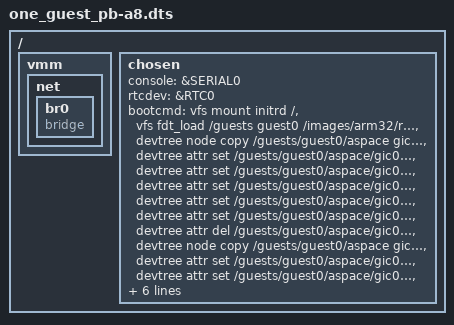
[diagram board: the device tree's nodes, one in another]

/dts-v1/;

#include "vexpress-a15.dtsi"

/ {
	vmm {
		net {
			br0 {
				device_type = "netswitch";
				compatible = "bridge";
			};
		};
	};

	chosen {
		console = &SERIAL0;
		rtcdev = &RTC0;
		bootcmd = /* Mount initrd device */
			  "vfs mount initrd /",

			  /* Load guest0 device tree from file */
			  "vfs fdt_load /guests guest0 /images/arm32/realview-pb-a8.dtb mem0,physical_size,physsize,0x06000000 net0,switch,string,br0 net1,switch,string,br0",

			  /* Replace guest0 GIC emulator with vGIC emulator */
			  "devtree node copy /guests/guest0/aspace gic0_cpu /guests/guest0/aspace/gic0",
			  "devtree attr set /guests/guest0/aspace/gic0_cpu manifest_type string real",
			  "devtree attr set /guests/guest0/aspace/gic0_cpu guest_physical_addr physaddr 0x1E000000",
			  "devtree attr set /guests/guest0/aspace/gic0_cpu host_physical_addr physaddr 0x0",
			  "devtree attr set /guests/guest0/aspace/gic0_cpu physical_size physsize 0x1000",
			  "devtree attr set /guests/guest0/aspace/gic0_cpu compatible string arm,vgic,cpu",
			  "devtree attr del /guests/guest0/aspace/gic0_cpu parent_irq",
			  "devtree node copy /guests/guest0/aspace gic0_dist /guests/guest0/aspace/gic0",
			  "devtree attr set /guests/guest0/aspace/gic0_dist guest_physical_addr physaddr 0x1E001000",
			  "devtree attr set /guests/guest0/aspace/gic0_dist physical_size physsize 0x1000",
			  "devtree attr set /guests/guest0/aspace/gic0_dist compatible string arm,vgic,dist",
			  "devtree attr set /guests/guest0/aspace/gic0_dist num_irq uint32 96",
			  "devtree node del /guests/guest0/aspace/gic0",

			  /* Create guest0 */
			  "guest create guest0",

			  /* Load guest0 images */
			  "vfs guest_load_list guest0 /images/arm32/realview-pb-a8/nor_flash.list",

			  /* Print banner */
			  "vfs cat /system/banner.txt";
	};
};
